# TZ10xx register map
File version: 0.1g
Registers are 32-bit, read-write, reset 0x0 unless marked. A register's access mark holds for its fields unless they carry their own. Offsets are from the block's base; [hi:lo] are bit positions; {n}, {i} and the like mark numbered series; 'fields as' and 'values as' point back to an identical list.

## pmulv (part 2 of 2)
Base 0x40000000
{0x494+4i} PRESCAL_UART{i} (i=0..2) — Prescaler setting (CD_UART{i}) 0x0: Stop 0x1: 1/1 frequency division 0x2: 1/2 frequency division 0x3: 1/3 frequency division 0x4: 1/4 frequency division 0x5: 1/5 frequency division 0x6: 1/6 frequency division 0x7: 1/7 frequency division 0x8: 1/8 frequency division 0x9: 1/9 frequency division 0xA: 1/10 frequency division 0xB: 1/12 frequency division 0xC: 1/18 frequency division 0xD: 1/24 frequency division 0xE: 1/36 frequency division 0xF: 1/48 frequency division
  [3:0] PSSEL_CD_UART{i} — CD_UART{i}
0x4A0 PRESCAL_ADCC12A — Prescaler setting (CD_ADCC12A) 0x0: Stop 0x1: 1/1 frequency division 0x2: 1/2 frequency division 0x3: reserved 0x4: 1/4 frequency division 0x5: reserved 0x6: 1/6 frequency division 0x7: reserved 0x8: 1/8 frequency division 0x9: reserved 0xA: 1/10 frequency division 0xB: 1/12 frequency division 0xC: 1/18 frequency division 0xD: 1/24 frequency division 0xE: 1/36 frequency division 0xF: 1/48 frequency division * With [CSM_ADCC12A]=0b101-111, use the setting of "0x1: 1/1 frequency division".
  [3:0] PSSEL_CD_ADCC12A — CD_ADCC12A
0x4A4 PRESCAL_ADCC24A — Prescaler setting (CD_ADCC24A) 0x0: Stop 0x1: 1/1 frequency division 0x2: 1/2 frequency division 0x3: reserved 0x4: 1/4 frequency division 0x5: reserved 0x6: 1/6 frequency division 0x7: reserved 0x8: 1/8 frequency division 0x9: reserved 0xA: 1/10 frequency division 0xB: 1/12 frequency division 0xC: 1/18 frequency division 0xD: 1/24 frequency division 0xE: 1/36 frequency division 0xF: 1/48 frequency division * With [CSM_ADCC24A]=0b101 or 0b111, use the setting of "0x1: 1/1 frequency division".
  [3:0] PSSEL_CD_ADCC24A — CD_ADCC24A
0x500 CONFIG_OSC12M — OSC12M control
  [0] OSC12M_EN — Enable control 0: Stops OSC. 1: Starts OSC. * The initial value is determined with a value stored in EFUSE.
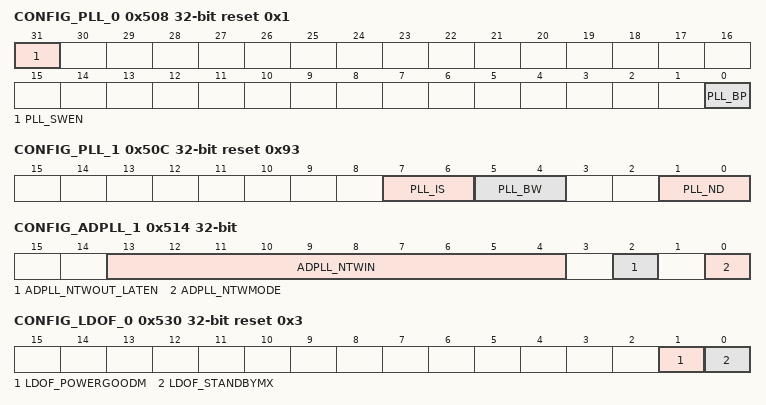
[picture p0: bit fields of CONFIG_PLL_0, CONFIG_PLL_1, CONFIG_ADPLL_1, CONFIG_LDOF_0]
0x508 CONFIG_PLL_0 reset 0x1 — PLL control
  [31] PLL_SWEN — SW control enable 0: Any terminals of PLL other than BP cannot be controlled from SW. 1: All terminals of PLL can be controlled from SW.
  [0] PLL_BP — Sets the bypass mode. 0: Normal mode 1: Bypass mode * Can be controlled from SW regardless of the value of [CONFIG_PLL_0].PLL_SWEN. * The initial value is determined with a value stored in EFUSE.
0x50C CONFIG_PLL_1 reset 0x93 — PLL control
  [7:6] PLL_IS — * Can be controlled from SW for [CONFIG_PLL_0].PLL_SWEN=1.
  [5:4] PLL_BW
  [1:0] PLL_ND
0x510 CONFIG_ADPLL_0 reset 0x7008 — ADPLL control
  [0] ADPLL_ENPLL — Operation control 0: Disable 1: Enable
0x514 CONFIG_ADPLL_1 — ADPLL control
  [13:4] ADPLL_NTWIN ro — Normalized Tuning Word input
  [2] ADPLL_NTWOUT_LATEN — Normalized Tuning Word output latch enable control 0: Disable 1: Enable
  [0] ADPLL_NTWMODE — Sets the Normalized Tuning Word mode. 0: Disable (Internal Mode) 1: Enable (External Mode)
0x528 CONFIG_DCDC_LVREG_1 — DCDC control
  [18] DCDC_SSFAST — Soft start control 0: Enable (slow) 1: Disable (fast)
0x530 CONFIG_LDOF_0 reset 0x3 — LDOF control
  [1] LDOF_POWERGOODM ro — Low voltage detection 0: Low voltage 1: Proper voltage * 0 -> 1 in the reset release sequence
  [0] LDOF_STANDBYMX — Enable control 0: Power down 1: Operation * 0 -> 1 in the reset release sequence
0x580 OVERRIDE_EFUSE_OSC12M reset 0x7 — OSC12M control * With [SELECT_EFUSE].SEL_EFUSE_OSC12M=0, EFUSE data is reloaded with write access. With [SELECT_EFUSE].SEL_EFUSE_OSC12M=1, write data is applied. * The initial value is determined with a value stored in EFUSE.
  [3:0] OVERRIDE_EFUSE_OSC12M_MAIN_GM — XO_Main GM adjustment 0b0000:Mode0 0b0001:Mode1 0b0011:Mode2 0b0111:Mode3 *The setting value other than above is prohibited.
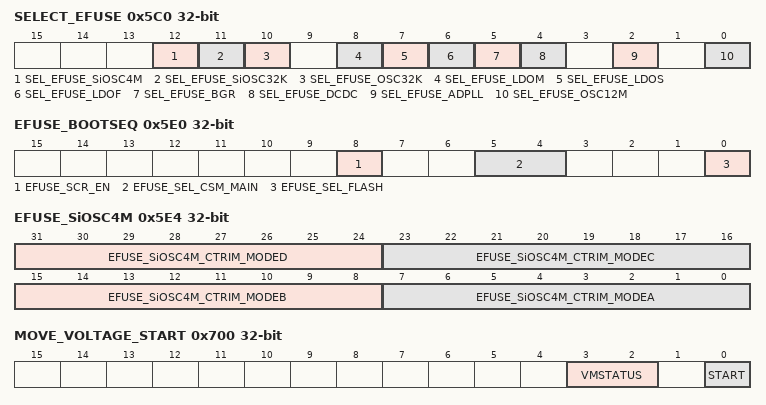
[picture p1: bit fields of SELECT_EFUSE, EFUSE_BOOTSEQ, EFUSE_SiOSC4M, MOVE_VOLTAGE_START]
0x5C0 SELECT_EFUSE — Selects data to be stored in the OVERRIDE register. 0: EFUSE data 1: Write data
  [12] SEL_EFUSE_SiOSC4M — SIOSC4M * Control of [OVERRIDE_EFUSE_SiOSC4M]
  [11] SEL_EFUSE_SiOSC32K — SIOSC32K * Control of [OVERRIDE_EFUSE_SiOSC32K]
  [10] SEL_EFUSE_OSC32K — OSC32K * Control of [OVERRIDE_EFUSE_OSC32K]
  [8] SEL_EFUSE_LDOM — LDOM * Control of [OVERRIDE_EFUSE_LDOM]
  [7] SEL_EFUSE_LDOS — LDOS * Control of [OVERRIDE_EFUSE_LDOS]
  [6] SEL_EFUSE_LDOF — LDOF * Control of [OVERRIDE_EFUSE_LDOF]
  [5] SEL_EFUSE_BGR — BGR * Control of [OVERRIDE_EFUSE_BGR_0],[OVERRIDE_EFUSE_BGR_1]
  [4] SEL_EFUSE_DCDC — DCDC * Control of [OVERRIDE_EFUSE_DCDC]
  [2] SEL_EFUSE_ADPLL — ADPLL * Control of [OVERRIDE_EFUSE_ADPLL_0] and [OVERRIDE_EFUSE_ADPLL_1]
  [0] SEL_EFUSE_OSC12M — OSC12M * Control of [OVERRIDE_EFUSE_OSC12M]
0x5DC EFUSE_REVISIONID ro — REVISIONID * The initial value is determined with a value stored in EFUSE.
  [31:0] EFUSE_REVISIONID — [31:28]:Reserved [27:24]:ID for geomagnetic sensor(revision ID for the mounted geomagnetic sensor chip) 0b0000:not mounted 0b0001:geomagnetic sensor identification1 0b0010:geomagnetic sensor identification2 [23:20]:ID for gyro sensor(revision ID for the mounted gyro sensor chip) 0b0000:not mounted 0b0001:gyro sensor identification1 0b0010:gyro sensor identification2 [19:16]:ID for accelaration sensor(revision ID for the mounted accelaration sensor chip) 0b0000:not mounted 0b0001:accelaration sensor identification1(ES) 0b0010:accelaration sensor identification2(CS) [15:12]:BLE ID(revision ID for the mounted BLE chip) 0b0000:not mounted 0b0001:BLE identification1(ROM2) 0b0010:BLE identification2(#3 ROM4) 0b0010:BLE identification3(#3 ROM5) [11:8] :FLASH ID(revision ID for the mounted FLASH chip) 0b0000:not mounted 0b0001:FLASH identification1 0b0010:FLASH identification2 [7:4] :MCU Major ID(for example,when the function update) 0b0000:ES1.0/ES1.1 0b0001:ES2.0 [3:0] :MCU Minor ID(for example,bug fix) *ES2.0a will be 32'h00023110.
0x5E0 EFUSE_BOOTSEQ ro — BOOTSEQ * The initial value is determined with a value stored in EFUSE.
  [8] EFUSE_SCR_EN — Control access to the internal FLASH. 0: disable 1: enable
  [5:4] EFUSE_SEL_CSM_MAIN — Selects CSM_MAIN at CPU start. 0b00: PLL 0b01: OSC12M other: SIOSC4M
  [0] EFUSE_SEL_FLASH — FLASH selection 0: winbond 1: macronics
0x5E4 EFUSE_SiOSC4M ro — SiOS4M Oscillation frequency adjustment * The initial value is determined with a value stored in EFUSE.
  [31:24] EFUSE_SiOSC4M_CTRIM_MODED — Mode D (0.9V)
  [23:16] EFUSE_SiOSC4M_CTRIM_MODEC — Mode C (1.0V)
  [15:8] EFUSE_SiOSC4M_CTRIM_MODEB — Mode B (1.1V)
  [7:0] EFUSE_SiOSC4M_CTRIM_MODEA — Mode A (1.2V)
0x600 BROWNOUTRESET — Brownout soft reset * Used together with the Brownout interrupt. The Brownout reset can be made by writing 1 to this register after a CPU interrupt.
  [0] BOR — [Write]1: Assert. 0: Ignored. [Read]1: Assert. 0: Deassert
0x700 MOVE_VOLTAGE_START — Voltage Mode transition setting
  [3:2] VMSTATUS ro — Voltage Mode status 0b00: Mode A (1.2V) 0b01: Mode B (1.1V) 0b10: Mode C (1.0V) 0b11: Mode D (0.9V)
  [0] START — Starts Voltage Mode transition. [Write]1: Start. 0: Ignored. [Read]1: Transition in progress. 0: Stop
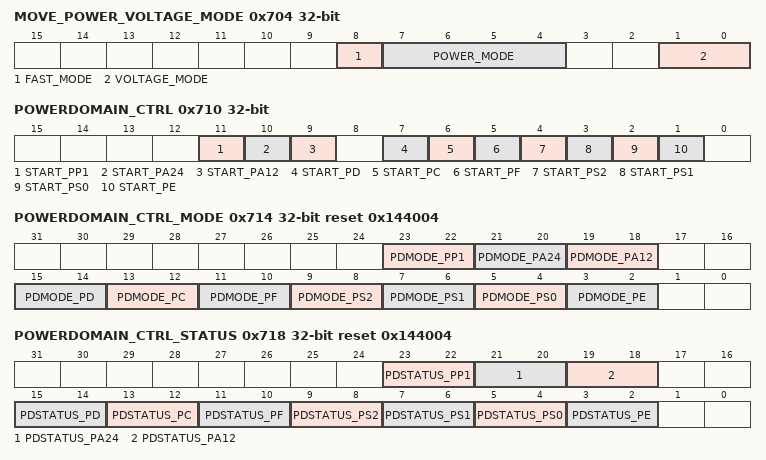
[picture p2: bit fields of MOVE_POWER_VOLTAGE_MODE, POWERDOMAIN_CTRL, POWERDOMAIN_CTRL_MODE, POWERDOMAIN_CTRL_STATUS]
0x704 MOVE_POWER_VOLTAGE_MODE — Power/Voltage Mode transition setting
  [8] FAST_MODE — High-speed return mode (only WAIT/WAIT-RETENTION/RETENTION) 0: Normal return mode Returns to Voltage Mode used before transition. 1: High-speed return mode ModeD is started up at return. So, a higher speed return is made because the mode is not returned to Voltage Mode before transition.
  [7:4] POWER_MODE — Sets a Power Mode transition destination. 0b0000: ACTIVE (Voltage Mode transition) 0b0001: SLEEP0 0b0010: SLEEP1 0b0011: SLEEP2 0b0100: WAIT 0b0101: WAIT-RETENTION 0b0110: reserved 0b0111: RETENTION 0b1000: RTC 0b1001: STOP other: reserved
  [1:0] VOLTAGE_MODE — Sets a Voltage Mode transition destination. 0b00: Mode A (1.2V) 0b01: Mode B (1.1V) 0b10: Mode C (1.0V) 0b11: Mode D (0.9V)
0x710 POWERDOMAIN_CTRL — Starts power supply domain control. [Write]1: Start. 0: Ignored. [Read]1: Transition in progress. 0: Stop * The power supply domain cannot be controlled for PM with SW.
  [11] START_PP1 — For PP1 power supply domain control
  [10] START_PA24 — For PA24 power supply domain control
  [9] START_PA12 — For PA12 power supply domain control
  [7] START_PD — For PD power supply domain control
  [6] START_PC — For PC power supply domain control
  [5] START_PF — For PF power supply domain control
  [4] START_PS2 — For PS2 power supply domain control
  [3] START_PS1 — For PS1 power supply domain control
  [2] START_PS0 — For PS0 power supply domain control
  [1] START_PE — For PE power supply domain control
0x714 POWERDOMAIN_CTRL_MODE reset 0x144004 — Sets a power supply domain control transition destination. 0b00: Power On 0b01: Power Off 0b10: RETENTION 0b11: WAIT (only PS0,PS1,and PS2 settable)
  [23:22] PDMODE_PP1 — For PP1 power supply domain control
  [21:20] PDMODE_PA24 — For PA24 power supply domain control
  [19:18] PDMODE_PA12 — For PA12 power supply domain control
  [15:14] PDMODE_PD — For PD power supply domain control
  [13:12] PDMODE_PC — For PC power supply domain control
  [11:10] PDMODE_PF — For PF power supply domain control
  [9:8] PDMODE_PS2 — For PS2 power supply domain control
  [7:6] PDMODE_PS1 — For PS1 power supply domain control
  [5:4] PDMODE_PS0 — For PS0 power supply domain control
  [3:2] PDMODE_PE — For PE power supply domain control
0x718 POWERDOMAIN_CTRL_STATUS ro reset 0x144004 — Power supply domain control status 0b00: Power On 0b01: Power Off 0b10: RETENTION 0b11: WAIT (only PS0,PS1,and PS2 used)
  [23:22] PDSTATUS_PP1 — For PP1 power supply domain control
  [21:20] PDSTATUS_PA24 — For PA24 power supply domain control
  [19:18] PDSTATUS_PA12 — For PA12 power supply domain control
  [15:14] PDSTATUS_PD — For PD power supply domain control
  [13:12] PDSTATUS_PC — For PC power supply domain control
  [11:10] PDSTATUS_PF — For PF power supply domain control
  [9:8] PDSTATUS_PS2 — For PS2 power supply domain control
  [7:6] PDSTATUS_PS1 — For PS1 power supply domain control
  [5:4] PDSTATUS_PS0 — For PS0 power supply domain control
  [3:2] PDSTATUS_PE — For PE power supply domain control
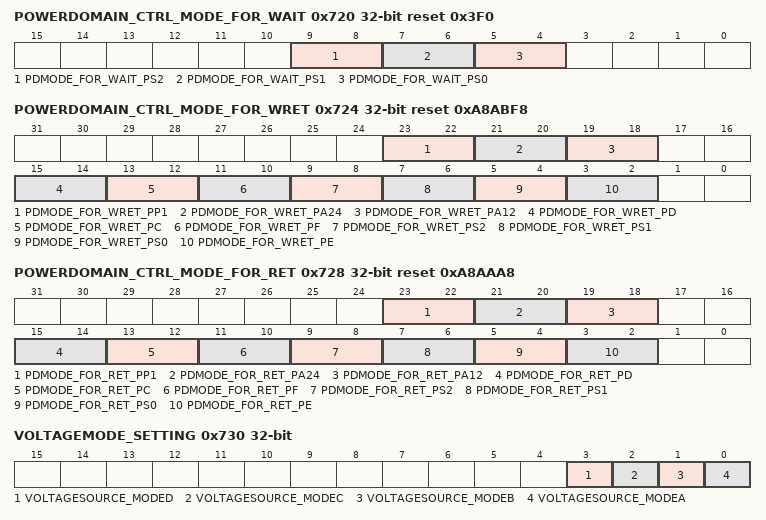
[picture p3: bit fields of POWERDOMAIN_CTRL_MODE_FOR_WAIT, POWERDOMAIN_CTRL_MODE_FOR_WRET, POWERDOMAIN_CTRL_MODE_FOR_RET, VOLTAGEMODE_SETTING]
0x720 POWERDOMAIN_CTRL_MODE_FOR_WAIT reset 0x3F0 — Sets a power supply domain control transition destination in WAIT mode. 0b00:PowerOn 0b01: Power Off (only PS1 and PS2 settable) 0b10: Setting prohibited 0b11: WAIT (only PS0,PS1,and PS2 used)
  [9:8] PDMODE_FOR_WAIT_PS2 — For PS2 power supply domain control
  [7:6] PDMODE_FOR_WAIT_PS1 — For PS1 power supply domain control
  [5:4] PDMODE_FOR_WAIT_PS0 — For PS0 power supply domain control
0x724 POWERDOMAIN_CTRL_MODE_FOR_WRET reset 0xA8ABF8 — Sets a power supply domain control transition destination in WAIT-RETENTION mode. 0b00: Power On 0b01: Power Off (P0 unsettable) 0b10:RETENTION (PS0,PS1,and PS2 unsettable) 0b11:WAIT (only PS0,PS1,and PS2 used)
  [23:22] PDMODE_FOR_WRET_PP1 — For PP1 power supply domain control
  [21:20] PDMODE_FOR_WRET_PA24 — For PA24 power supply domain control
  [19:18] PDMODE_FOR_WRET_PA12 — For PA12 power supply domain control
  [15:14] PDMODE_FOR_WRET_PD — For PD power supply domain control
  [13:12] PDMODE_FOR_WRET_PC — For PC power supply domain control
  [11:10] PDMODE_FOR_WRET_PF — For PF power supply domain control
  [9:8] PDMODE_FOR_WRET_PS2 — For PS2 power supply domain control
  [7:6] PDMODE_FOR_WRET_PS1 — For PS1 power supply domain control
  [5:4] PDMODE_FOR_WRET_PS0 — For PS0 power supply domain control
  [3:2] PDMODE_FOR_WRET_PE — For PE power supply domain control
0x728 POWERDOMAIN_CTRL_MODE_FOR_RET reset 0xA8AAA8 — Sets a power supply domain control transition destination in RETENTION mode. 0b00: Setting prohibited 0b01: Power Off 0b10: RETENTION 0b11: Setting prohibited
  [23:22] PDMODE_FOR_RET_PP1 — For PP1 power supply domain control
  [21:20] PDMODE_FOR_RET_PA24 — For PA24 power supply domain control
  [19:18] PDMODE_FOR_RET_PA12 — For PA12 power supply domain control
  [15:14] PDMODE_FOR_RET_PD — For PD power supply domain control
  [13:12] PDMODE_FOR_RET_PC — For PC power supply domain control
  [11:10] PDMODE_FOR_RET_PF — For PF power supply domain control
  [9:8] PDMODE_FOR_RET_PS2 — For PS2 power supply domain control
  [7:6] PDMODE_FOR_RET_PS1 — For PS1 power supply domain control
  [5:4] PDMODE_FOR_RET_PS0 — For PS0 power supply domain control
  [3:2] PDMODE_FOR_RET_PE — For PE power supply domain control
0x730 VOLTAGEMODE_SETTING
  [3] VOLTAGESOURCE_MODED — 0:LDOS, 1:LDOM
  [2] VOLTAGESOURCE_MODEC — 0:DCDC, 1:LDOM
  [1] VOLTAGESOURCE_MODEB — 0:DCDC, 1:LDOM
  [0] VOLTAGESOURCE_MODEA ro — 0:DCDC
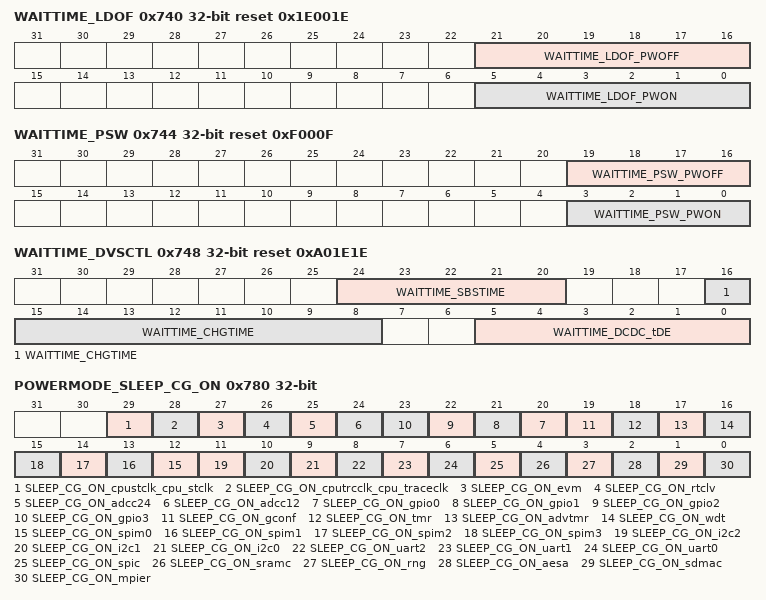
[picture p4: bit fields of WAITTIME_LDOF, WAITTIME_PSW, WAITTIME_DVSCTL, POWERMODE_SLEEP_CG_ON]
0x740 WAITTIME_LDOF reset 0x1E001E — Wait time at LDOF Power On/Off switching 0us(0x00)-630us(0x3f) *units of 10us
  [21:16] WAITTIME_LDOF_PWOFF — Sets the period from Off control until power to the target is turned off (initial value: 300us).
  [5:0] WAITTIME_LDOF_PWON — Sets the period from On control until power is stably supplied to the target (initial value: 300us).
0x744 WAITTIME_PSW reset 0xF000F — Wait time at Internal Power Switch Power On/Off switching (only PS0,PS1,and PS2 used) 1us(0x0)-16us(0xf) *units of 1us
  [19:16] WAITTIME_PSW_PWOFF — Sets the period from Off control until power to the target is turned off (initial value: 16us)
  [3:0] WAITTIME_PSW_PWON — Sets the period from On control until power is stably supplied to the target (initial value: 16us).
0x748 WAITTIME_DVSCTL reset 0xA01E1E — Wait time at power source or voltage switching *units of 1us
  [24:20] WAITTIME_SBSTIME — Wait time until voltage is switched (step time when voltage is increased every 0.1V) (initial value: 10us) 0us(0x00)-31us(0x1f) * 0 setting: No step execution * units of 1us
  [16:8] WAITTIME_CHGTIME — Wait time until the power source is switched (initial value: 30us) 0us(0x000)-511us(0x1ff) *units of 1us
  [5:0] WAITTIME_DCDC_tDE — Wait time from a rising edge of DCDC EN_DCDCREF until a rising edge of EN_DCDC (initial value: 30us) 0us(0x00)-63us(0x3f) * units of 1us
0x780 POWERMODE_SLEEP_CG_ON — Block to be subject to clock gating ON addition control in SLEEP mode 0: No clock stop addition control 1: Clock stop addition control available
  [29] SLEEP_CG_ON_cpustclk_cpu_stclk — CPU SYSTICK clock
  [28] SLEEP_CG_ON_cputrcclk_cpu_traceclk — CPU trace clock
  [27] SLEEP_CG_ON_evm — EVM
  [26] SLEEP_CG_ON_rtclv — RTCLV
  [25] SLEEP_CG_ON_adcc24 — ADCC24
  [24] SLEEP_CG_ON_adcc12 — ADCC12
  [n+20] SLEEP_CG_ON_gpio{n} (n=0..3) — GPIO{n}
  [19] SLEEP_CG_ON_gconf — GCONF
  [18] SLEEP_CG_ON_tmr — TMR
  [17] SLEEP_CG_ON_advtmr — ADVTMR
  [16] SLEEP_CG_ON_wdt — WDT
  [n+12] SLEEP_CG_ON_spim{n} (n=0..3) — SPIM{n}
  [11] SLEEP_CG_ON_i2c2 — I2C2
  [10] SLEEP_CG_ON_i2c1 — I2C1
  [9] SLEEP_CG_ON_i2c0 — I2C0
  [8] SLEEP_CG_ON_uart2 — UART2
  [7] SLEEP_CG_ON_uart1 — UART1
  [6] SLEEP_CG_ON_uart0 — UART0
  [5] SLEEP_CG_ON_spic — SPIC
  [4] SLEEP_CG_ON_sramc — SRAMC
  [3] SLEEP_CG_ON_rng — RNG
  [2] SLEEP_CG_ON_aesa — AESA
  [1] SLEEP_CG_ON_sdmac — SDMAC
  [0] SLEEP_CG_ON_mpier — MPIER
0x790 POWERMODE_SLEEP_PRESCAL — prescaler setting in SLEEP mode
  [0] SLEEP_PSSEL_mpierclk_cpu_fclk — CPU free-run clock 0: 1/1 frequency division 1: 1/4 frequency division * Only with a mode transition by sleeping. With a mode transition by sleepdeep, CPU free-tun clock is stopped. * Frequency=fCSM_MAIN/(DIVPSSEL_CD_MPIER * DIVSLEEP_PSSEL_mpierclk_cpu_fclk)
0x1124 CG_ON_PC_SCRT reset 0x4 — Clock gating ON (PC) [Write]1: Clock stops. 0: Ignored. [Read]1: Clock is stopped. 0: Clock is being supplied. * Also changed by writing to [CG_ON_POWERDOMAIN_SCRT].CG_PC_SCRT and [CG_OFF_POWERDOMAIN_SCRT].CG_PC_SCRT.
  [2] CG_cputrcclk_cpu_traceclk — CPU trace clock
0x11A4 CG_OFF_PC_SCRT reset 0xB — Clock gating OFF (PC) [Write]1: Clock is supplied. 0: Ignored. [Read]1: Clock is being supplied. 0: Clock is stopped. * Also changed by writing to [CG_ON_POWERDOMAIN_SCRT].CG_PC_SCRT and [CG_OFF_POWERDOMAIN_SCRT].CG_PC_SCRT.
  [2] CG_cputrcclk_cpu_traceclk — CPU trace clock
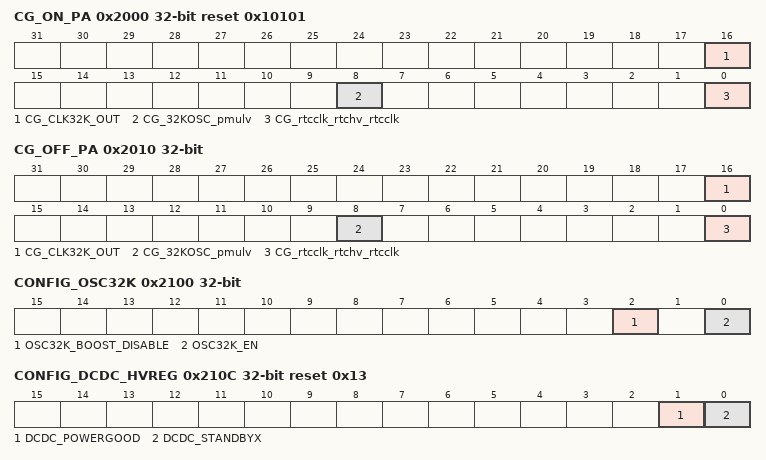
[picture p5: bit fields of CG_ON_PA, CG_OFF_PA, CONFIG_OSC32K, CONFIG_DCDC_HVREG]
0x2000 CG_ON_PA reset 0x10101 — Clock gating ON (PA) [Write]1: Clock stops. 0: Ignored. [Read]1: Clock is stopped. 0: Clock is being supplied.
  [16] CG_CLK32K_OUT — External clock
  [8] CG_32KOSC_pmulv — PMULV clock
  [0] CG_rtcclk_rtchv_rtcclk — RTCHV clock
0x2010 CG_OFF_PA — Clock gating OFF (PA) [Write]1: Clock is supplied. 0: Ignored. [Read]1: Clock is being supplied. 0: Clock is stopped.
  fields as CG_ON_PA
0x2020 SRST_ON_PA reset 0x1 — Soft reset ON (PA) [Write]1: Reset assert. 0: Ignored. [Read]1: Reset assert in progress. 0: Reset deassert in progress.
  [0] SRST_asyncrst_rtchv_rtcrstn — RTCHV reset
0x2030 SRST_OFF_PA — Soft reset OFF (PA) [Write]1: Reset deassert. 0: Ignored. [Read]1: Reset deassert in progress. 0: Reset assert in progress.
  [0] SRST_asyncrst_rtchv_rtcrstn — RTCHV reset
0x2080 CSM_RTC — Clock source setting (CD_RTC)
  [0] CSMSEL_RTC — 0b0:OSC32K 0b1:SIOSC32K
0x20C0 RTCLV_RSYNC_SETTING — RTCLV timer reset selection
  [1:0] RTCLV_RSYNC_SETTING — 0b00: Synchronized to SiOSC4M 0b01: Synchronized to OSC32K/SIOSC32K (1 cycle) 0b10: Synchronized to OSC32K/SIOSC32K (2 cycles) 0b11: reserved * OSC32K and SIOSC32K are switched with [CSM_RTC].
0x2100 CONFIG_OSC32K — OSC32K control
  [2] OSC32K_BOOST_DISABLE — High-speed startup disable control 0: High-speed mode enable 1: High-speed mode disable
  [0] OSC32K_EN — Enable control 0: Stops OSC. 1: Starts OSC.
0x2104 CONFIG_SiOSC32K — SIOSC32K control
  [0] SiOSC32K_EN — Enable control 0: Power down 1: Oscillation
0x2108 CONFIG_SiOSC4M reset 0x1 — SIOSC4M control
  [4] SiOSC4M_CTRIM_LAT — CTRIM latch control 0: Through latch 1: Hold (100ns or more)
0x210C CONFIG_DCDC_HVREG reset 0x13 — DCDC control
  [1] DCDC_POWERGOOD ro — Low voltage detection 0: Low voltage 1: Proper voltage * 0 -> 1 in the power-on sequence
  [0] DCDC_STANDBYX — DCDC enable control 0: Power down 1: Operation * 0 -> 1 in the power-on sequence
0x2118 CONFIG_LVD_0 reset 0x3 — LVD control
  [1] LVD_POWERGOOD ro — Low voltage detection 0: Low voltage 1: Proper voltage * 0 -> 1 in the power-on sequence
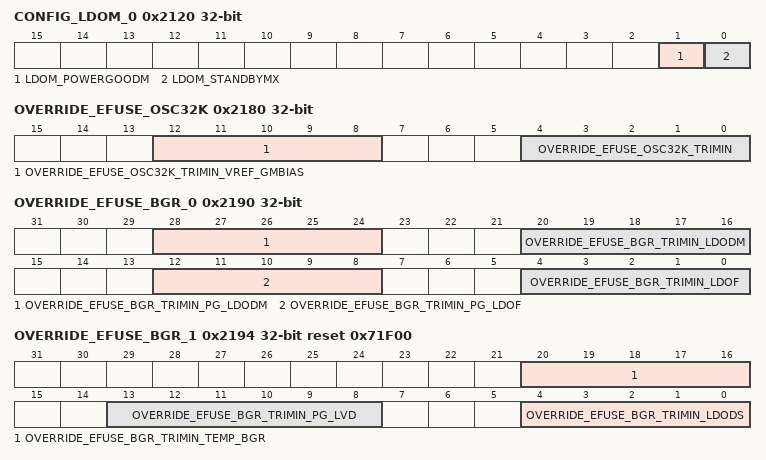
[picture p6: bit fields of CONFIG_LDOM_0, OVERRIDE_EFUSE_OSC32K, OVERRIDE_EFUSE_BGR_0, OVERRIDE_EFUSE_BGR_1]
0x2120 CONFIG_LDOM_0 — LDOM control
  [1] LDOM_POWERGOODM ro — Low voltage detection 0: Low voltage 1: Proper voltage
  [0] LDOM_STANDBYMX — Enable control 0: Power down 1: Operation
0x2124 CONFIG_LDOM_1 reset 0x3 — LDOM control
  [2:0] LDOM_SETOUT — Sets output voltage. 0bx00: 1.2V 0bx01: 1.1V 0bx10: 1.0V 0bx11: 0.9V (x: don't care)
0x2130 CONFIG_LDOS_0 — LDOS control
  [0] LDOS_STANDBYMX — Enable control 0: Power down 1: Operation
0x2134 CONFIG_LDOS_1 reset 0x3 — LDOS control
  [2:0] LDOS_SETOUT — Sets output voltage. 0b000: 1.2V 0b001: 1.1V 0b010: 1.0V 0b011: 0.9V 0b1xx: 0.8V (x: don't care)
0x2180 OVERRIDE_EFUSE_OSC32K — OSC32K control * With [SELECT_EFUSE].SEL_EFUSE_OSC32K=0, EFUSE data is reloaded with write access. With [SELECT_EFUSE].SEL_EFUSE_OSC32K=1, write data is applied. * The initial value is determined with a value stored in EFUSE.
  [12:8] OVERRIDE_EFUSE_OSC32K_TRIMIN_VREF_GMBIAS — Voltage adjustment bit for Gm constant bias (current switching) 0b00000:Mode0/Mode3 0b00001:Mode1 0b00010:Mode2 0b00011:Mode4/Mode5/Mode6/Mode7 *The setting value other than above are prohited
  [4:0] OVERRIDE_EFUSE_OSC32K_TRIMIN — Adjustment bit (current switching or the like assumed) 0b00110:Mode0/Mode1/Mode2/Mode4 0b00111:Mode3/Mode5 0b01111:Mode6 0b11111:Mode7 *The setting value other than above are prohited
0x2184 OVERRIDE_EFUSE_SiOSC32K — SIOSC32K control * With [SELECT_EFUSE].SEL_EFUSE_SIOSC32K=0, EFUSE data is reloaded with write access. With [SELECT_EFUSE].SEL_EFUSE_SIOSC32K=1, write data is applied. * The initial value is determined with a value stored in EFUSE.
  [4:0] OVERRIDE_EFUSE_SiOSC32K_TRIMIN_FREQ — Oscillation frequency adjustment
0x2188 OVERRIDE_EFUSE_SiOSC4M — SIOSC4M control * With [SELECT_EFUSE].SEL_EFUSE_SIOSC4M=0, EFUSE data is reloaded with write access. With [SELECT_EFUSE].SEL_EFUSE_SIOSC4M=1, write data s applied.
  [7:0] OVERRIDE_EFUSE_SiOSC4M_CTRIM — Oscillation frequency adjustment
0x2190 OVERRIDE_EFUSE_BGR_0 — BGR control * With [SELECT_EFUSE].SEL_EFUSE_BGR=0, EFUSE data is reloaded with right access. With [SELECT_EFUSE].SEL_EFUSE_BGR=1, write data is applied. * The initial value is determined with a value stored in EFUSE.
  [28:24] OVERRIDE_EFUSE_BGR_TRIMIN_PG_LDODM — LDOM POWERGOOD output voltage adjustment
  [20:16] OVERRIDE_EFUSE_BGR_TRIMIN_LDODM — LDOM output voltage adjustment
  [12:8] OVERRIDE_EFUSE_BGR_TRIMIN_PG_LDOF — LDOF POWERGOOD output voltage adjustment
  [4:0] OVERRIDE_EFUSE_BGR_TRIMIN_LDOF — LDOF output voltage adjustment
0x2194 OVERRIDE_EFUSE_BGR_1 reset 0x71F00 — BGR control * With [SELECT_EFUSE].SEL_EFUSE_BGR=0, EFUSE data is reloaded with right access. With [SELECT_EFUSE].SEL_EFUSE_BGR=1, write data is applied. * The initial value is determined with a value stored in EFUSE.
  [20:16] OVERRIDE_EFUSE_BGR_TRIMIN_TEMP_BGR — BGR temperature characteristic adjustment
  [13:8] OVERRIDE_EFUSE_BGR_TRIMIN_PG_LVD — LVD POWERGOOD output voltage adjustment
  [4:0] OVERRIDE_EFUSE_BGR_TRIMIN_LDODS — LDOS output voltage adjustment
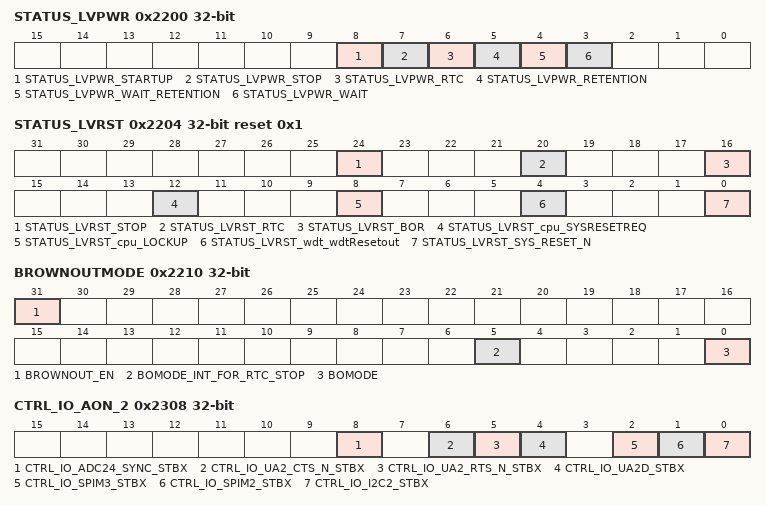
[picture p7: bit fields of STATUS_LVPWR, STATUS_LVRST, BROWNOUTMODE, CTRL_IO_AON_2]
0x2200 STATUS_LVPWR — Power Mode status * [8:0]=0x000: ACTIVE mode
  [8] STATUS_LVPWR_STARTUP — 1: STARTUP mode. 0: Others * 1 -> 0 in the reset release sequence
  [7] STATUS_LVPWR_STOP — 1: STOP mode. 0: Others
  [6] STATUS_LVPWR_RTC — 1: RTC mode. 0: Others
  [5] STATUS_LVPWR_RETENTION — 1: RETENTION mode. 0: Others
  [4] STATUS_LVPWR_WAIT_RETENTION — 1: WAIT-RETENTION mode. 0: Others
  [3] STATUS_LVPWR_WAIT — 1: WAIT mode. 0: Others
0x2204 STATUS_LVRST reset 0x1 — Reset factor [Write]1: Factor clear. 0: Ignored
  [24] STATUS_LVRST_STOP — [Read]1: Return from STOP mode. 0: Others
  [20] STATUS_LVRST_RTC — [Read]1: Return from RTC mode. 0: Others
  [16] STATUS_LVRST_BOR — [Read]1: BOR. 0: Others
  [12] STATUS_LVRST_cpu_SYSRESETREQ — [Read]1: CPU system reset request. 0: Others
  [8] STATUS_LVRST_cpu_LOCKUP — [Read]1: Reset by a CPU hardware fault. 0: Others
  [4] STATUS_LVRST_wdt_wdtResetout — [Read]1: WDT reset. 0: Others
  [0] STATUS_LVRST_SYS_RESET_N — [Read]1: MCU_SYS_RESET_N terminal. 0: Others * 0 -> 1 in the power-on sequence
0x2210 BROWNOUTMODE — Brownout mode switching
  [31] BROWNOUT_EN — Brownout detection enable 0: Disable 1: Enable
  [5] BOMODE_INT_FOR_RTC_STOP — In RTC/STOP mode 0: Return to ACTIVE mode by BrownOut interrupt 1: BrownOut reset is asserted by BrownOut interrupt.
  [0] BOMODE — BrownOut Mode 0: Brownout reset 1:Brownout interrupt
0x2300 CTRL_IO_AON_0 reset 0x1 — IO reset control (AON(PM) IO domain)
  [0] CTRL_IO_AON_PM_RESX — 0: pull-up/pull-down/Hi-z(Depends on the IO cell) 1: (Depends on the LATI status.) * 0 -> in the reset release sequence
0x2304 CTRL_IO_AON_1 — IO setting retention control (AON(PM) IO domain)
  [0] CTRL_IO_AON_PM_LATI — (For RESX=H) 0: Normal 1: retain
0x2308 CTRL_IO_AON_2 — IO input standby control (AON(PM) IO domain) 0: Standby. 1: Active
  [8] CTRL_IO_ADC24_SYNC_STBX — MCU_ADC24_SYNC terminal
  [6] CTRL_IO_UA2_CTS_N_STBX — MCU_UA2_CTS_N terminal
  [5] CTRL_IO_UA2_RTS_N_STBX — MCU_UA2_RTS_N terminal
  [4] CTRL_IO_UA2D_STBX — MCU_UA2_RXD terminal MCU_UA2_TXD terminal
  [2] CTRL_IO_SPIM3_STBX — MCU_SPIM3_CS_N terminal MCU_SPIM3_CLK terminal MCU_SPIM3_MOSI terminal MCU_SPIM3_MISO terminal
  [1] CTRL_IO_SPIM2_STBX — MCU_SPIM2_CS_N terminal MCU_SPIM2_CLK terminal MCU_SPIM2_MOSI terminal MCU_SPIM2_MISO terminal
  [0] CTRL_IO_I2C2_STBX — MCU_I2C2_DATA terminal MCU_I2C2_CLK terminal
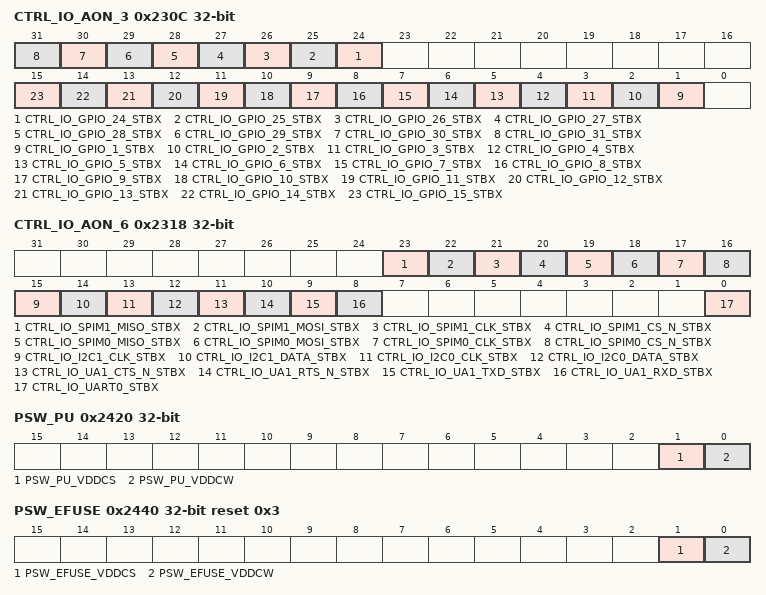
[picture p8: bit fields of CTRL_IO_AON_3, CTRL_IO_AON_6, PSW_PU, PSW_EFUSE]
0x230C CTRL_IO_AON_3 — IO input standby control (AON(PM) IO domain) 0: Standby. 1: Active
  [n] CTRL_IO_GPIO_{n}_STBX (n=24..31) — MCU_GPIO_{n} terminal
  [n] CTRL_IO_GPIO_{n}_STBX (n=1..15) — MCU_GPIO_{n} terminal
0x2310 CTRL_IO_AON_4 reset 0x1 — IO reset control (AON(PP1) IO domain)
  [0] CTRL_IO_AON_PP1_RESX — 0: pull-up/pull-down/Hi-z(Depends on the IO cell) 1: (Depends on the LATI status.) * 0 -> in the reset release sequence
0x2314 CTRL_IO_AON_5 — IO setting retention control (AON(PP1) IO domain)
  [0] CTRL_IO_AON_PP1_LATI — (For RESX=H) 0: Normal 1: retain
0x2318 CTRL_IO_AON_6 — IO input standby control (AON(PP1) IO domain) 0: Standby. 1: Active
  [23] CTRL_IO_SPIM1_MISO_STBX — MCU_SPIM1_MISO terminal
  [22] CTRL_IO_SPIM1_MOSI_STBX — MCU_SPIM1_MOSI terminal
  [21] CTRL_IO_SPIM1_CLK_STBX — MCU_SPIM1_CLK terminal
  [20] CTRL_IO_SPIM1_CS_N_STBX — MCU_SPIM1_CS_N terminal
  [19] CTRL_IO_SPIM0_MISO_STBX — MCU_SPIM0_MISO terminal
  [18] CTRL_IO_SPIM0_MOSI_STBX — MCU_SPIM0_MOSI terminal
  [17] CTRL_IO_SPIM0_CLK_STBX — MCU_SPIM0_CLK terminal
  [16] CTRL_IO_SPIM0_CS_N_STBX — MCU_SPIM0_CS_N terminal
  [15] CTRL_IO_I2C1_CLK_STBX — MCU_I2C1_CLK terminal
  [14] CTRL_IO_I2C1_DATA_STBX — MCU_I2C1_DATA terminal
  [13] CTRL_IO_I2C0_CLK_STBX — MCU_I2C0_CLK terminal
  [12] CTRL_IO_I2C0_DATA_STBX — MCU_I2C0_DATA terminal
  [11] CTRL_IO_UA1_CTS_N_STBX — MCU_UA1_CTS_N terminal
  [10] CTRL_IO_UA1_RTS_N_STBX — MCU_UA1_RTS_N terminal
  [9] CTRL_IO_UA1_TXD_STBX — MCU_UA1_TXD terminal
  [8] CTRL_IO_UA1_RXD_STBX — MCU_UA1_RXD terminal
  [0] CTRL_IO_UART0_STBX — MCU_UA0_RXD terminal MCU_UA0_TXD terminal
0x2420 PSW_PU — Internal Power Switch control of the PU power supply domain [Write]1: Power is supplied. 0: Power is turned off. [Read]1: Power is being supplied. 0: Power is being turned off.
  [1] PSW_PU_VDDCS — VDDC strong switch control
  [0] PSW_PU_VDDCW — VDDC weak switch control
0x2440 PSW_EFUSE reset 0x3 — Internal Power Switch control of the EFUS power supply domain [Write]1: Power is supplied. 0: Power is turned off. [Read]1: Power is being supplied. 0: Power is being turned off.
  [1] PSW_EFUSE_VDDCS — VDDC strong switch control * 0 -> 1 in the reset release sequence
  [0] PSW_EFUSE_VDDCW — VDDC weak switch control * 0 -> 1 in the reset release sequence
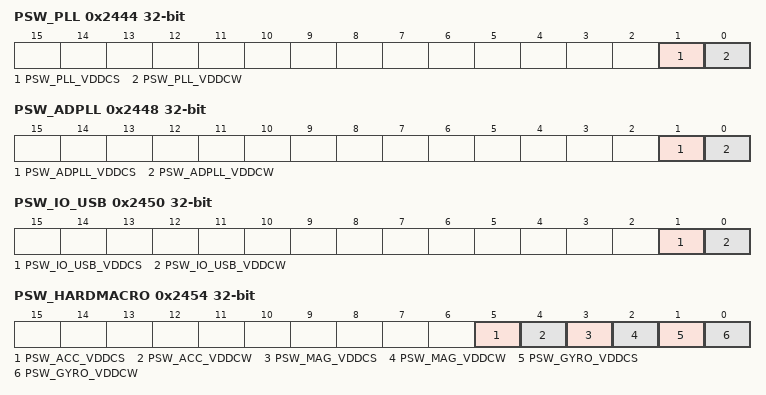
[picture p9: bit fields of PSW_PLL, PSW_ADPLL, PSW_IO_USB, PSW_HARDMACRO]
0x2444 PSW_PLL — Internal Power Switch control of the PLL power supply domain [Write]1: Power is supplied. 0: Power is turned off. [Read]1: Power is being supplied. 0: Power is being turned off.
  [1] PSW_PLL_VDDCS — VDDC strong switch control * Switching from 0 to 1 may occur in the reset release sequence.
  [0] PSW_PLL_VDDCW — VDDC weak switch control * Switching from 0 to 1 may occur in the reset release sequence.
0x2448 PSW_ADPLL — Internal Power Switch control of the ADPLL power supply domain [Write]1: Power is supplied. 0: Power is turned off. [Read]1: Power is being supplied. 0: Power is being turned off.
  [1] PSW_ADPLL_VDDCS — VDDC strong switch control
  [0] PSW_ADPLL_VDDCW — VDDC weak switch control
0x2450 PSW_IO_USB — Internal Power Switch control of the IO_USB [Write]1: Power is supplied. 0: Power is turned off. [Read]1: Power is being supplied. 0: Power is being turned off.
  [1] PSW_IO_USB_VDDCS — VDDC strong switch control
  [0] PSW_IO_USB_VDDCW — VDDC weak switch control
0x2454 PSW_HARDMACRO — Internal Power Switch control of Hard Macro [Write]1: Power is supplied. 0: Power is turned off. [Read]1: Power is being supplied. 0: Power is being turned off.
  [5] PSW_ACC_VDDCS — ACC VDDC strong switch control
  [4] PSW_ACC_VDDCW — ACC VDDC weak switch control
  [3] PSW_MAG_VDDCS — MAG VDDC strong switch control
  [2] PSW_MAG_VDDCW — MAG VDDC weak switch control
  [1] PSW_GYRO_VDDCS — GYRO VDDC strong switch control
  [0] PSW_GYRO_VDDCW — GYRO VDDC weak switch control
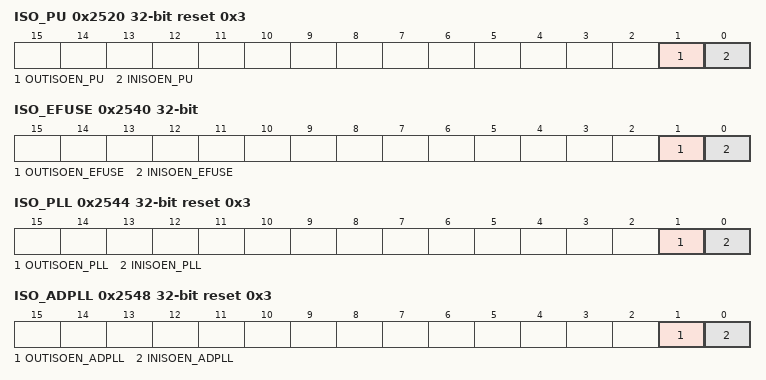
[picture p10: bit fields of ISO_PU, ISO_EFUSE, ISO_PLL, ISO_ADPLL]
0x2520 ISO_PU reset 0x3 — PU power supply domain isolation control [Write]1: Signal is fixed. 0: No signal is fixed. [Read]1: Signal is being fixed. 0: No signal is fixed.
  [1] OUTISOEN_PU — Output signal isolation control
  [0] INISOEN_PU — Input signal isolation control
0x2540 ISO_EFUSE — EFUSE power supply domain isolation control [Write]1: Signal is fixed. 0: No signal is fixed. [Read]1: Signal is being fixed. 0: No signal is fixed.
  [1] OUTISOEN_EFUSE — Output signal isolation control * 1 -> 0 in the reset release sequence
  [0] INISOEN_EFUSE — Input signal isolation control * 1 -> 0 in the reset release sequence
0x2544 ISO_PLL reset 0x3 — PLL power supply domain isolation control [Write]1: Signal is fixed. 0: No signal is fixed. [Read]1: Signal is being fixed. 0: No signal is fixed.
  [1] OUTISOEN_PLL — Output signal isolation control * Switching from 1 to 0 may occur in the reset release sequence.
  [0] INISOEN_PLL — Input signal isolation control * Switching from 1 to 0 may occur in the reset release sequence.
0x2548 ISO_ADPLL reset 0x3 — ADPLL power supply domain isolation control [Write]1: Signal is fixed. 0: No signal is fixed. [Read]1: Signal is being fixed. 0: No signal is fixed.
  [1] OUTISOEN_ADPLL — Output signal isolation control
  [0] INISOEN_ADPLL — Input signal isolation control
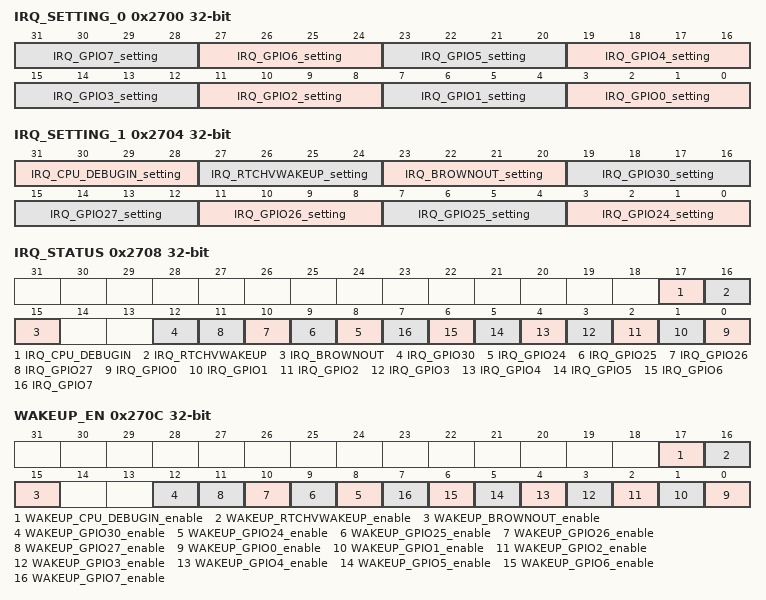
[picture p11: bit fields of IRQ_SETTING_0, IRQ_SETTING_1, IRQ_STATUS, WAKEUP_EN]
0x2700 IRQ_SETTING_0 — Setting of Wakeup detection * The following "bit*" is a bit number in 4 bits of setting registers for every interrupt. bit0: Rising edge detection bit1: Falling edge detection bit2: Low level detection bit3: High level detection 1: enable 0: disable * If 1 is written to bit0 and bit1, the both edge is detected.
  [4n+3:4n] IRQ_GPIO{n}_setting (n=0..7) — MCU_GPIO_{n} terminal
0x2704 IRQ_SETTING_1 — Setting of Wakeup detection * The following "bit*" is a bit number in 4 bits of setting registers for every interrupt. bit0: Rising edge detection bit1: Falling edge detection bit2: Low level detection bit3: High level detection 1: enable 0: disable * If 1 is written to bit0 and bit1, the both edge is detected.
  [31:28] IRQ_CPU_DEBUGIN_setting — CPU debug interrupt
  [27:24] IRQ_RTCHVWAKEUP_setting — RTCHV wakeup interrupt
  [23:20] IRQ_BROWNOUT_setting — Brownout interrupt
  [19:16] IRQ_GPIO30_setting — MCU_GPIO_30 terminal
  [4n-93:4n-96] IRQ_GPIO{n}_setting (n=24..27) — MCU_GPIO_{n} terminal
0x2708 IRQ_STATUS — Cause of Wakeup [Write]1: Wakeup cause clear. 0: Ignored [Read]1: Wakeup cause available. 0: No wakeup cause * All detected cause can be checked.
  [17] IRQ_CPU_DEBUGIN — CPU debug interrupt
  [16] IRQ_RTCHVWAKEUP — RTCHV wakeup interrupt
  [15] IRQ_BROWNOUT — Brownout interrupt
  [12] IRQ_GPIO30 — MCU_GPIO_30 terminal
  [n-16] IRQ_GPIO{n} (n=24..27) — MCU_GPIO_{n} terminal
  [n] IRQ_GPIO{n} (n=0..7) — MCU_GPIO_{n} terminal
0x270C WAKEUP_EN — Setting of Wakeup interrupt 0: Wakeup interrupt disable 1: Wakeup interrupt enable
  [17] WAKEUP_CPU_DEBUGIN_enable — CPU debug interrupt
  [16] WAKEUP_RTCHVWAKEUP_enable — RTCHV wakeup interrupt
  [15] WAKEUP_BROWNOUT_enable — Brownout interrupt
  [12] WAKEUP_GPIO30_enable — MCU_GPIO_30 terminal
  [n-16] WAKEUP_GPIO{n}_enable (n=24..27) — MCU_GPIO_{n} terminal
  [n] WAKEUP_GPIO{n}_enable (n=0..7) — MCU_GPIO_{n} terminal
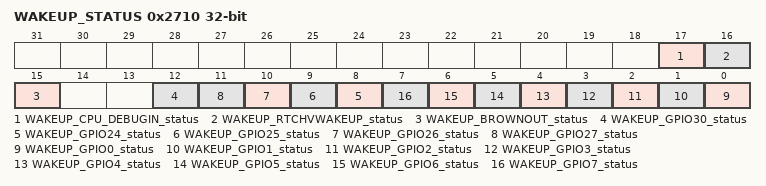
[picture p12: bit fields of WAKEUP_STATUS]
0x2710 WAKEUP_STATUS ro — Cause of Wakeup interrupt 0: No wakeup interrupt cause 1: Wakeup interrupt available * Only cause that set 1 to [WAKEUP_EN] can be checked.
  [17] WAKEUP_CPU_DEBUGIN_status — CPU debug interrupt
  [16] WAKEUP_RTCHVWAKEUP_status — RTCHV wakeup interrupt
  [15] WAKEUP_BROWNOUT_status — Brownout interrupt
  [12] WAKEUP_GPIO30_status — MCU_GPIO_30 terminal
  [n-16] WAKEUP_GPIO{n}_status (n=24..27) — MCU_GPIO_{n} terminal
  [n] WAKEUP_GPIO{n}_status (n=0..7) — MCU_GPIO_{n} terminal
0x2800 CPU_DEBUG reset 0x1 — CPU debug control
  [0] CPU_DBGEN — [Write]0: JTAG connection disable. 1: Ignored [Read]0: JTAG connection disable. 1: JTAG connection enable
0x2804 CTRL_DEBUG_ACCESS — Debugger access control
  [0] CTRL_DEBUG_ACCESS — 0: JTAG connection disable 1: JTAG connection enable * When the [EFUSE_BOOTSEQ].EFUSE_SCR_EN is 1, this function is effective.
0x2808 CTRL_CDBGPWRUPREQ reset 0x1 — Reset Control at the JTAG connection
  [0] CDBGPWRUPREQ_EN — control by the following cause of reset: - CPU system reset request - Reset by the CPU hardware fault - WDT reset 0: all blocks except for the PA power domain 1: CPU core and WDT(when the cause of reset is WDT reset)
